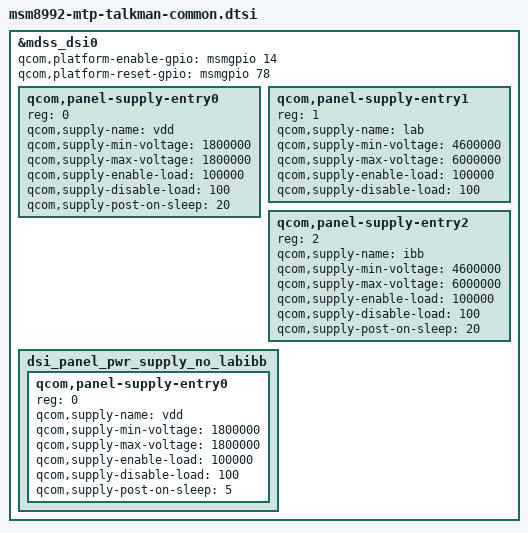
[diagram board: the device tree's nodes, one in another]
&mdss_dsi0 {
	//qcom,dsi-pref-prim-pan = <&dsi_default_gpio_0>;
	// vdd-supply = <&pm8941_lvs3>;
	qcom,platform-enable-gpio = <&msmgpio 14 0>;
	qcom,platform-reset-gpio = <&msmgpio 78 0>;
	// qcom,platform-lane-config = [];

	qcom,panel-supply-entry0 {
		reg = <0>;
		qcom,supply-name = "vdd";
		qcom,supply-min-voltage = <1800000>;
		qcom,supply-max-voltage = <1800000>;
		qcom,supply-enable-load = <100000>;
		qcom,supply-disable-load = <100>;
		qcom,supply-post-on-sleep = <20>;
	};

	qcom,panel-supply-entry1 {
		reg = <1>;
		qcom,supply-name = "lab";
		qcom,supply-min-voltage = <4600000>;
		qcom,supply-max-voltage = <6000000>;
		qcom,supply-enable-load = <100000>;
		qcom,supply-disable-load = <100>;
	};

	qcom,panel-supply-entry2 {
		reg = <2>;
		qcom,supply-name = "ibb";
		qcom,supply-min-voltage = <4600000>;
		qcom,supply-max-voltage = <6000000>;
		qcom,supply-enable-load = <100000>;
		qcom,supply-disable-load = <100>;
		qcom,supply-post-on-sleep = <20>;
	};

	dsi_panel_pwr_supply_no_labibb: dsi_panel_pwr_supply_no_labibb {
		#address-cells = <1>;
		#size-cells = <0>;

		qcom,panel-supply-entry0 {
			reg = <0>;
			qcom,supply-name = "vdd";
			qcom,supply-min-voltage = <1800000>;
			qcom,supply-max-voltage = <1800000>;
			qcom,supply-enable-load = <100000>;
			qcom,supply-disable-load = <100>;
			qcom,supply-post-on-sleep = <5>;
		};
	};
};
